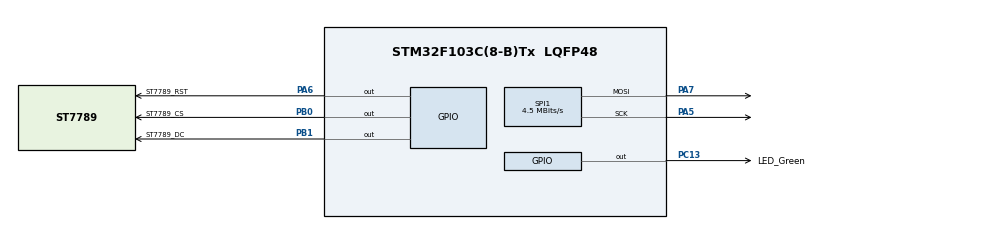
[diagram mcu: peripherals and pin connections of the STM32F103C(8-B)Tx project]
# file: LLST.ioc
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Dma.Request0=SPI1_TX
Dma.SPI1_TX.0.Direction=DMA_MEMORY_TO_PERIPH
Dma.SPI1_TX.0.Instance=DMA1_Channel3
Dma.SPI1_TX.0.MemDataAlignment=DMA_MDATAALIGN_BYTE
Dma.SPI1_TX.0.MemInc=DMA_MINC_ENABLE
Dma.SPI1_TX.0.Mode=DMA_NORMAL
Dma.SPI1_TX.0.PeriphDataAlignment=DMA_PDATAALIGN_BYTE
Dma.SPI1_TX.0.PeriphInc=DMA_PINC_DISABLE
Dma.SPI1_TX.0.Priority=DMA_PRIORITY_MEDIUM
Mcu.Family=STM32F1
Mcu.Name=STM32F103C(8-B)Tx
Mcu.Package=LQFP48
NVIC.DMA1_Channel3_IRQn=true\:0\:0\:false\:false\:true\:false\:true\:true
NVIC.PriorityGroup=NVIC_PRIORITYGROUP_4
NVIC.TIM2_IRQn=true\:3\:0\:true\:false\:true\:true\:true\:true
PA13.Mode=Serial_Wire
PA13.Signal=SYS_JTMS-SWDIO
PA14.Mode=Serial_Wire
PA14.Signal=SYS_JTCK-SWCLK
PA5.Mode=TX_Only_Simplex_Unidirect_Master
PA5.Signal=SPI1_SCK
PA6.GPIO_Label=ST7789_RST
PA6.Signal=GPIO_Output
PA7.Mode=TX_Only_Simplex_Unidirect_Master
PA7.Signal=SPI1_MOSI
PB0.GPIO_Label=ST7789_CS
PB0.Signal=GPIO_Output
PB1.GPIO_Label=ST7789_DC
PB1.Signal=GPIO_Output
PC13-TAMPER-RTC.GPIO_Label=LED_Green
PC13-TAMPER-RTC.Signal=GPIO_Output
PD0-OSC_IN.Mode=HSE-External-Oscillator
PD0-OSC_IN.Signal=RCC_OSC_IN
PD1-OSC_OUT.Mode=HSE-External-Oscillator
PD1-OSC_OUT.Signal=RCC_OSC_OUT
ProjectManager.HeapSize=0x200
ProjectManager.StackSize=0x400
ProjectManager.TargetToolchain=MDK-ARM V5.32
RCC.AHBFreq_Value=72000000
RCC.APB1CLKDivider=RCC_HCLK_DIV2
RCC.APB1Freq_Value=36000000
RCC.APB1TimFreq_Value=72000000
RCC.APB2Freq_Value=72000000
RCC.APB2TimFreq_Value=72000000
RCC.HCLKFreq_Value=72000000
RCC.PLLMUL=RCC_PLL_MUL9
RCC.PLLSourceVirtual=RCC_PLLSOURCE_HSE
RCC.SYSCLKFreq_VALUE=72000000
RCC.SYSCLKSource=RCC_SYSCLKSOURCE_PLLCLK
RCC.USBFreq_Value=72000000
SPI1.BaudRatePrescaler=SPI_BAUDRATEPRESCALER_16
SPI1.CalculateBaudRate=4.5 MBits/s
SPI1.Direction=SPI_DIRECTION_2LINES
SPI1.Mode=SPI_MODE_MASTER
SPI1.VirtualType=VM_MASTER
TIM2.Period=719
TIM2.Prescaler=9999
VP_TIM2_VS_ClockSourceINT.Mode=Internal
board=custom

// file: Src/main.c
/* USER CODE BEGIN Header */
/**
  ******************************************************************************
  * @file           : main.c
  * @brief          : Main program body
  ******************************************************************************
  * @attention
  *
  * Copyright (c) 2026 STMicroelectronics.
  * All rights reserved.
  *
  * This software is licensed under terms that can be found in the LICENSE file
  * in the root directory of this software component.
  * If no LICENSE file comes with this software, it is provided AS-IS.
  *
  ******************************************************************************
  */
/* USER CODE END Header */
#include "main.h"
#include "dma.h"
#include "spi.h"
#include "tim.h"
#include "gpio.h"

/* USER CODE BEGIN Includes */
#include "st7789.h"
/* USER CODE END Includes */

void SystemClock_Config(void);

int main(void)
{

  /* MCU Configuration--------------------------------------------------------*/

  /* Reset of all peripherals, Initializes the Flash interface and the Systick. */
  LL_APB2_GRP1_EnableClock(LL_APB2_GRP1_PERIPH_AFIO);
  LL_APB1_GRP1_EnableClock(LL_APB1_GRP1_PERIPH_PWR);

  /* System interrupt init*/
  NVIC_SetPriorityGrouping(NVIC_PRIORITYGROUP_4);

  /* SysTick_IRQn interrupt configuration */
  NVIC_SetPriority(SysTick_IRQn, NVIC_EncodePriority(NVIC_GetPriorityGrouping(),15, 0));

  /** NOJTAG: JTAG-DP Disabled and SW-DP Enabled
  */
  LL_GPIO_AF_Remap_SWJ_NOJTAG();

  /* Configure the system clock */
  SystemClock_Config();

  /* Initialize all configured peripherals */
  MX_GPIO_Init();
  MX_DMA_Init();
  MX_SPI1_Init();
  MX_TIM2_Init();
  /* USER CODE BEGIN 2 */
	LL_SPI_Enable(SPI1);
	LL_TIM_EnableIT_UPDATE(TIM2);   // 允许更新中断
	LL_TIM_EnableCounter(TIM2);     // 启动计数
	ST7789_Init();
  /* USER CODE END 2 */

  /* Infinite loop */
  while (1)
  {

  }
}

void SystemClock_Config(void)
{
  LL_FLASH_SetLatency(LL_FLASH_LATENCY_2);
  while(LL_FLASH_GetLatency()!= LL_FLASH_LATENCY_2)
  {
  }
  LL_RCC_HSE_Enable();

   /* Wait till HSE is ready */
  while(LL_RCC_HSE_IsReady() != 1)
  {

  }
  LL_RCC_PLL_ConfigDomain_SYS(LL_RCC_PLLSOURCE_HSE_DIV_1, LL_RCC_PLL_MUL_9);
  LL_RCC_PLL_Enable();

   /* Wait till PLL is ready */
  while(LL_RCC_PLL_IsReady() != 1)
  {

  }
  LL_RCC_SetAHBPrescaler(LL_RCC_SYSCLK_DIV_1);
  LL_RCC_SetAPB1Prescaler(LL_RCC_APB1_DIV_2);
  LL_RCC_SetAPB2Prescaler(LL_RCC_APB2_DIV_1);
  LL_RCC_SetSysClkSource(LL_RCC_SYS_CLKSOURCE_PLL);

   /* Wait till System clock is ready */
  while(LL_RCC_GetSysClkSource() != LL_RCC_SYS_CLKSOURCE_STATUS_PLL)
  {

  }
  LL_Init1msTick(72000000);
  LL_SetSystemCoreClock(72000000);
}

void Error_Handler(void)
{
  __disable_irq();
  while (1)
  {
  }
}
